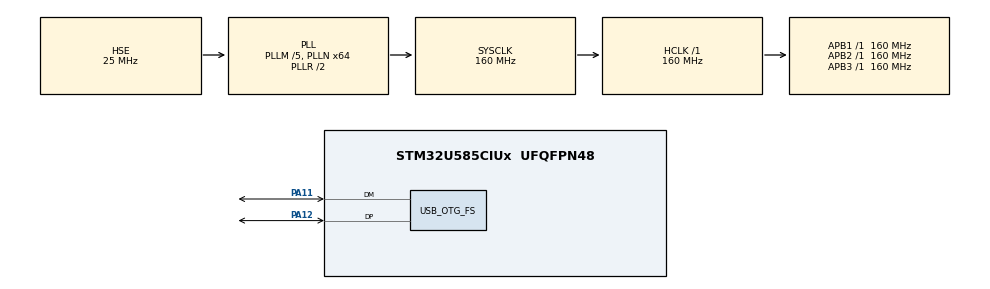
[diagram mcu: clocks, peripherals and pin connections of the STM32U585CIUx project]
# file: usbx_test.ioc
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CORTEX_M33_NS.userName=CORTEX_M33
Mcu.Family=STM32U5
Mcu.Name=STM32U585CIUx
Mcu.Package=UFQFPN48
NVIC.OTG_FS_IRQn=true\:0\:0\:false\:false\:true\:true\:true\:true
NVIC.PriorityGroup=NVIC_PRIORITYGROUP_4
PA11.Mode=Device_Only
PA11.Signal=USB_OTG_FS_DM
PA12.Mode=Device_Only
PA12.Signal=USB_OTG_FS_DP
PA13\ (JTMS/SWDIO).Mode=Serial_Wire
PA13\ (JTMS/SWDIO).Signal=DEBUG_JTMS-SWDIO
PA14\ (JTCK/SWCLK).Mode=Serial_Wire
PA14\ (JTCK/SWCLK).Signal=DEBUG_JTCK-SWCLK
PC14-OSC32_IN\ (PC14).Mode=LSE-External-Oscillator
PC14-OSC32_IN\ (PC14).Signal=RCC_OSC32_IN
PC15-OSC32_OUT\ (PC15).Mode=LSE-External-Oscillator
PC15-OSC32_OUT\ (PC15).Signal=RCC_OSC32_OUT
PH0-OSC_IN\ (PH0).Mode=HSE-External-Oscillator
PH0-OSC_IN\ (PH0).Signal=RCC_OSC_IN
PH1-OSC_OUT\ (PH1).Mode=HSE-External-Oscillator
PH1-OSC_OUT\ (PH1).Signal=RCC_OSC_OUT
ProjectManager.HeapSize=0x400
ProjectManager.StackSize=0x2000
ProjectManager.TargetToolchain=STM32CubeIDE
RCC.ADCFreq_Value=16000000
RCC.AHBFreq_Value=160000000
RCC.APB1Freq_Value=160000000
RCC.APB1TimFreq_Value=160000000
RCC.APB2Freq_Value=160000000
RCC.APB2TimFreq_Value=160000000
RCC.APB3Freq_Value=160000000
RCC.CortexFreq_Value=160000000
RCC.EPOD_VALUE=25000000
RCC.HCLKFreq_Value=160000000
RCC.HSE_VALUE=25000000
RCC.HSI48_VALUE=48000000
RCC.HSI_VALUE=16000000
RCC.LSIDIV_VALUE=32000
RCC.MSI_VALUE=4000000
RCC.PLLM=5
RCC.PLLN=64
RCC.PLLSourceVirtual=RCC_PLLSOURCE_HSE
RCC.SYSCLKFreq_VALUE=160000000
RCC.SYSCLKSource=RCC_SYSCLKSOURCE_PLLCLK
RCC.USBFreq_Value=48000000
RCC.VCOOutputFreq_Value=320000000
USBX.AZRTOS_APP_MEM_ALLOCATION_METHOD_STANDALONE=1
USBX.BSP.number=1
USBX.Core_System=1
USBX.USBD_CDCACM_EPINCMD_ADDR=2
USBX.USBD_CDCACM_EPIN_ADDR=1
USBX.USBX_DEVICE_SYS_SIZE=10*1024
USBX.UX_DEVICE_APP_MEM_POOL_SIZE_STANDALONE=16384
USBX.UX_DEVICE_CDC_ACM=1
USBX.UX_DEVICE_CLASS_CDC_ACM_WRITE_AUTO_ZLP=1
USBX.UX_Device_Controller=1
USBX.UX_Device_CoreStack=1
USBX.UX_ENABLE_ERROR_CHECKING=1
USBX.UX_SLAVE_REQUEST_DATA_MAX_LENGTH=512
USBX0.BSP.STBoard=false
USBX0.BSP.api=Unknown
USBX0.BSP.condition=SEMAOoUSBOoOTGOoFSOoDEVICEOoFOROoUSBX & \!DIE455
USBX0.BSP.instance=USB_OTG_FS
USBX0.BSP.ip=USB_OTG_FS
USBX0.BSP.mode=Device_Only
USBX0.BSP.name=USBDevice
USBX0.BSP.solution=USB_OTG_FS
USB_OTG_FS.VirtualMode=Device_Only
VP_ICACHE_VS_ENABLE_ICACHE_MEMORY.Mode=Memoryregions
VP_LPBAMQUEUE_VS_QUEUE.Mode=QUEUEMODE
VP_LPBAM_VS_SIG1.Mode=SmartRun
VP_LPBAM_VS_SIG4.Mode=LPDMA1
VP_MEMORYMAP_VS_MEMORYMAP.Mode=CurAppReg
VP_PWR_VS_SECSignals.Mode=Security/Privilege
VP_USBX_Core_System.Mode=Core_System
VP_USBX_UX\ Device\ CDC\ ACM\ Class_FS.Mode=UX_Device_class_CDC_ACM_FS
VP_USBX_UX\ Device\ Controller_FS.Mode=UX_Device_Controller_FS
VP_USBX_UX\ Device\ CoreStack_FS.Mode=UX_Device_CoreStack_FS
board=custom

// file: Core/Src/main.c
/* USER CODE BEGIN Header */
/**
  ******************************************************************************
  * @file           : main.c
  * @brief          : Main program body
  ******************************************************************************
  * @attention
  *
  * Copyright (c) 2025 STMicroelectronics.
  * All rights reserved.
  *
  * This software is licensed under terms that can be found in the LICENSE file
  * in the root directory of this software component.
  * If no LICENSE file comes with this software, it is provided AS-IS.
  *
  ******************************************************************************
  */
/* USER CODE END Header */
#include "main.h"
#include "icache.h"
#include "app_usbx_device.h"
#include "gpio.h"

/* USER CODE BEGIN Includes */
#include "usb_otg.h"
/* USER CODE END Includes */

/* USER CODE BEGIN PD */
typedef enum {
  ECHO_DEVICE_IDLE = 0,
  ECHO_DEVICE_WAIT,
  ECHO_DEVICE_SEND
} ECHO_DEVICE_STATE;
/* USER CODE END PD */

void SystemClock_Config(void);

int main(void)
{

  /* USER CODE BEGIN 1 */
  UINT status;
  /* USER CODE END 1 */

  /* MCU Configuration--------------------------------------------------------*/

  /* Reset of all peripherals, Initializes the Flash interface and the Systick. */
  HAL_Init();

  /* Configure the system clock */
  SystemClock_Config();

  /* Initialize all configured peripherals */
  MX_GPIO_Init();
  MX_USBX_Device_Init();
  MX_ICACHE_Init();
  /* USER CODE BEGIN 2 */

  MX_USB_OTG_FS_PCD_Init();
  HAL_PCDEx_SetRxFiFo(&hpcd_USB_OTG_FS, 0x80);
  HAL_PCDEx_SetTxFiFo(&hpcd_USB_OTG_FS, 0, USBD_MAX_EP0_SIZE / 4);
  HAL_PCDEx_SetTxFiFo(&hpcd_USB_OTG_FS, 1, USBD_CDCACM_EPIN_FS_MPS / 4);
  HAL_PCDEx_SetTxFiFo(&hpcd_USB_OTG_FS, 2, USBD_CDCACM_EPINCMD_FS_MPS / 4);

  status = _ux_dcd_stm32_initialize((ULONG)USB_OTG_FS, (ULONG)&hpcd_USB_OTG_FS);
  if (status != UX_SUCCESS)
  {
    Error_Handler();
  }

  HAL_PCD_Start(&hpcd_USB_OTG_FS);
  /* USER CODE END 2 */

  /* Infinite loop */
  /* USER CODE BEGIN WHILE */
  uint32_t tick = HAL_GetTick();
  uint32_t tick_usb = tick;
  uint32_t tick_usb_tx = tick;
  uint8_t buf[256];
  ULONG actual_length = 0;
  ECHO_DEVICE_STATE echo_state = ECHO_DEVICE_IDLE;
  UINT ux_status = UX_STATE_RESET;

  while (1)
  {
    tick = HAL_GetTick();
    if(tick >= tick_usb)
    {
      tick_usb = tick + 1;
      _ux_system_tasks_run();
    }

    if(tick >= tick_usb_tx)
    {
      tick_usb_tx = tick + 1;

      extern UX_SLAVE_CLASS_CDC_ACM  *cdc_acm;
      if(cdc_acm != UX_NULL)
      {
        ux_status = ux_device_class_cdc_acm_read_run(cdc_acm, buf, sizeof(buf), &actual_length);
        if(ux_status == UX_STATE_NEXT && actual_length > 0)
        {
          echo_state = ECHO_DEVICE_SEND;
        }
        switch(echo_state)
        {
        case ECHO_DEVICE_SEND:
          ux_status = ux_device_class_cdc_acm_write_run(cdc_acm, buf, actual_length, &actual_length);

          if (ux_status != UX_STATE_WAIT)
          {
            /* Reset state.  */
            echo_state = ECHO_DEVICE_IDLE;
            break;
          }
          echo_state = ECHO_DEVICE_WAIT;
          break;

        case ECHO_DEVICE_WAIT:
          /* Continue to run state machine.  */
          ux_status = ux_device_class_cdc_acm_write_run(cdc_acm, UX_NULL, 0, &actual_length);
          /* Check if dataset is transmitted */
          if (ux_status <= UX_STATE_NEXT)
          {
            echo_state = ECHO_DEVICE_IDLE;
            actual_length = 0;
          }
          /* Keep waiting.  */
          break;
        default:
          break;
        }
      }
    }
    /* USER CODE END WHILE */

  }
}

void SystemClock_Config(void)
{
  RCC_OscInitTypeDef RCC_OscInitStruct = {0};
  RCC_ClkInitTypeDef RCC_ClkInitStruct = {0};

  /** Configure the main internal regulator output voltage
  */
  if (HAL_PWREx_ControlVoltageScaling(PWR_REGULATOR_VOLTAGE_SCALE1) != HAL_OK)
  {
    Error_Handler();
  }

  /** Initializes the CPU, AHB and APB buses clocks
  */
  RCC_OscInitStruct.OscillatorType = RCC_OSCILLATORTYPE_HSI48|RCC_OSCILLATORTYPE_HSE;
  RCC_OscInitStruct.HSEState = RCC_HSE_ON;
  RCC_OscInitStruct.HSI48State = RCC_HSI48_ON;
  RCC_OscInitStruct.PLL.PLLState = RCC_PLL_ON;
  RCC_OscInitStruct.PLL.PLLSource = RCC_PLLSOURCE_HSE;
  RCC_OscInitStruct.PLL.PLLMBOOST = RCC_PLLMBOOST_DIV2;
  RCC_OscInitStruct.PLL.PLLM = 5;
  RCC_OscInitStruct.PLL.PLLN = 64;
  RCC_OscInitStruct.PLL.PLLP = 2;
  RCC_OscInitStruct.PLL.PLLQ = 2;
  RCC_OscInitStruct.PLL.PLLR = 2;
  RCC_OscInitStruct.PLL.PLLRGE = RCC_PLLVCIRANGE_0;
  RCC_OscInitStruct.PLL.PLLFRACN = 0;
  if (HAL_RCC_OscConfig(&RCC_OscInitStruct) != HAL_OK)
  {
    Error_Handler();
  }

  /** Initializes the CPU, AHB and APB buses clocks
  */
  RCC_ClkInitStruct.ClockType = RCC_CLOCKTYPE_HCLK|RCC_CLOCKTYPE_SYSCLK
                              |RCC_CLOCKTYPE_PCLK1|RCC_CLOCKTYPE_PCLK2
                              |RCC_CLOCKTYPE_PCLK3;
  RCC_ClkInitStruct.SYSCLKSource = RCC_SYSCLKSOURCE_PLLCLK;
  RCC_ClkInitStruct.AHBCLKDivider = RCC_SYSCLK_DIV1;
  RCC_ClkInitStruct.APB1CLKDivider = RCC_HCLK_DIV1;
  RCC_ClkInitStruct.APB2CLKDivider = RCC_HCLK_DIV1;
  RCC_ClkInitStruct.APB3CLKDivider = RCC_HCLK_DIV1;

  if (HAL_RCC_ClockConfig(&RCC_ClkInitStruct, FLASH_LATENCY_4) != HAL_OK)
  {
    Error_Handler();
  }
}

void Error_Handler(void)
{
  __disable_irq();
  while (1)
  {
  }
}
